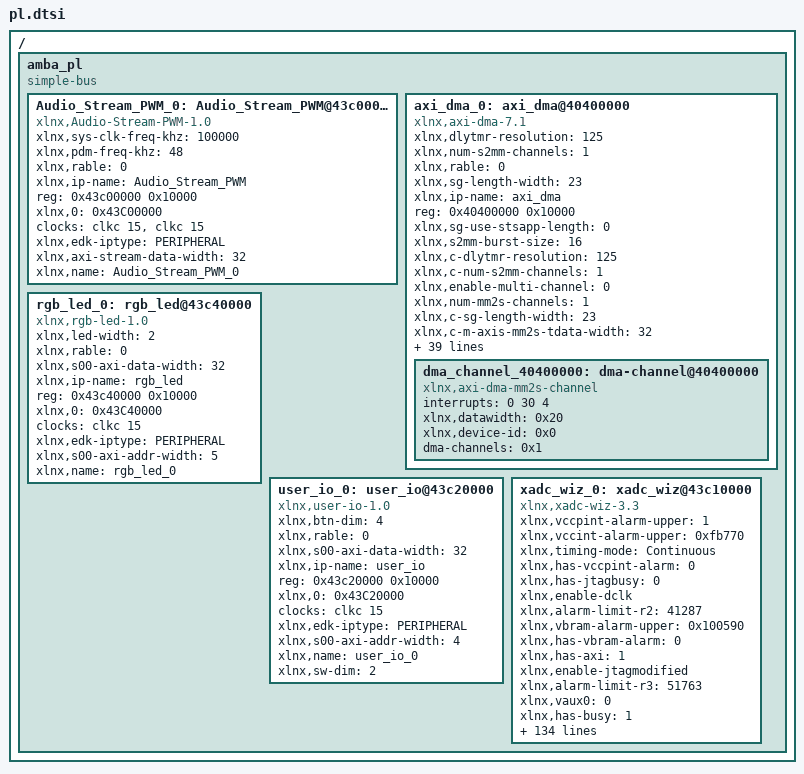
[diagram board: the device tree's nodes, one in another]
/ {
	amba_pl: amba_pl {
		ranges;
		compatible = "simple-bus";
		#address-cells = <1>;
		#size-cells = <1>;
		Audio_Stream_PWM_0: Audio_Stream_PWM@43c00000 {
			compatible = "xlnx,Audio-Stream-PWM-1.0";
			xlnx,sys-clk-freq-khz = <100000>;
			xlnx,pdm-freq-khz = <48>;
			xlnx,rable = <0>;
			xlnx,ip-name = "Audio_Stream_PWM";
			reg = <0x43c00000 0x10000>;
			xlnx,0 = <0x43C00000>;
			clocks = <&clkc 15>, <&clkc 15>;
			xlnx,edk-iptype = "PERIPHERAL";
			status = "okay";
			xlnx,axi-stream-data-width = <32>;
			clock-names = "S_AXIS_MM2S_ACLK" , "s_axi_aclk";
			xlnx,name = "Audio_Stream_PWM_0";
		};
		axi_dma_0: axi_dma@40400000 {
			xlnx,dlytmr-resolution = <125>;
			xlnx,num-s2mm-channels = <1>;
			xlnx,rable = <0>;
			xlnx,sg-length-width = <23>;
			xlnx,ip-name = "axi_dma";
			reg = <0x40400000 0x10000>;
			xlnx,sg-use-stsapp-length = <0>;
			xlnx,s2mm-burst-size = <16>;
			xlnx,c-dlytmr-resolution = <125>;
			xlnx,c-num-s2mm-channels = <1>;
			xlnx,enable-multi-channel = <0>;
			xlnx,num-mm2s-channels = <1>;
			xlnx,c-sg-length-width = <23>;
			interrupt-names = "mm2s_introut";
			compatible = "xlnx,axi-dma-7.1" , "xlnx,axi-dma-1.00.a";
			xlnx,c-m-axis-mm2s-tdata-width = <32>;
			xlnx,c-sg-use-stsapp-length = <0>;
			xlnx,c-s2mm-burst-size = <16>;
			xlnx,mm2s-burst-size = <16>;
			xlnx,c-enable-multi-channel = <0>;
			xlnx,c-num-mm2s-channels = <1>;
			interrupt-parent = <&intc>;
			xlnx,include-s2mm-dre = <0>;
			xlnx,c-mm2s-burst-size = <16>;
			status = "okay";
			xlnx,c-include-s2mm-dre = <0>;
			xlnx,include-mm2s-dre = <0>;
			xlnx,name = "axi_dma_0";
			interrupts = < 0 30 4 >;
			xlnx,c-include-sg = <0>;
			xlnx,c-m-axi-s2mm-data-width = <32>;
			xlnx,include-s2mm-sf = <1>;
			xlnx,c-include-mm2s-dre = <0>;
			xlnx,include-s2mm = <0>;
			clocks = <&clkc 15>, <&clkc 15>;
			xlnx,addrwidth = <0x20>;
			xlnx,c-m-axi-mm2s-data-width = <32>;
			xlnx,edk-iptype = "PERIPHERAL";
			xlnx,c-include-s2mm-sf = <1>;
			xlnx,include-mm2s-sf = <1>;
			clock-names = "m_axi_mm2s_aclk" , "s_axi_lite_aclk";
			xlnx,c-include-s2mm = <0>;
			xlnx,c-addr-width = <32>;
			xlnx,c-single-interface = <0>;
			xlnx,include-mm2s = <1>;
			xlnx,c-s-axis-s2mm-tdata-width = <32>;
			xlnx,s2mm-data-width = <0x20>;
			xlnx,c-include-mm2s-sf = <1>;
			xlnx,prmry-is-aclk-async = <0>;
			xlnx,c-include-mm2s = <1>;
			xlnx,increase-throughput = <0>;
			xlnx,micro-dma = <0>;
			xlnx,mm2s-data-width = <0x20>;
			xlnx,c-prmry-is-aclk-async = <0>;
			xlnx,c-sg-include-stscntrl-strm = <0>;
			xlnx,c-increase-throughput = <0>;
			xlnx,c-micro-dma = <0>;
			dma_channel_40400000: dma-channel@40400000 {
				interrupts = <0 30 4>;
				xlnx,datawidth = <0x20>;
				xlnx,device-id = <0x0>;
				compatible = "xlnx,axi-dma-mm2s-channel";
				dma-channels = <0x1>;
			};
		};
		rgb_led_0: rgb_led@43c40000 {
			compatible = "xlnx,rgb-led-1.0";
			xlnx,led-width = <2>;
			xlnx,rable = <0>;
			xlnx,s00-axi-data-width = <32>;
			xlnx,ip-name = "rgb_led";
			reg = <0x43c40000 0x10000>;
			xlnx,0 = <0x43C40000>;
			clocks = <&clkc 15>;
			xlnx,edk-iptype = "PERIPHERAL";
			status = "okay";
			xlnx,s00-axi-addr-width = <5>;
			clock-names = "s00_axi_aclk";
			xlnx,name = "rgb_led_0";
		};
		user_io_0: user_io@43c20000 {
			compatible = "xlnx,user-io-1.0";
			xlnx,btn-dim = <4>;
			xlnx,rable = <0>;
			xlnx,s00-axi-data-width = <32>;
			xlnx,ip-name = "user_io";
			reg = <0x43c20000 0x10000>;
			xlnx,0 = <0x43C20000>;
			clocks = <&clkc 15>;
			xlnx,edk-iptype = "PERIPHERAL";
			status = "okay";
			clock-names = "s00_axi_aclk";
			xlnx,s00-axi-addr-width = <4>;
			xlnx,name = "user_io_0";
			xlnx,sw-dim = <2>;
		};
		xadc_wiz_0: xadc_wiz@43c10000 {
			xlnx,vccpint-alarm-upper = <1>;
			xlnx,vccint-alarm-upper = <0xfb770>;
			xlnx,timing-mode = "Continuous";
			xlnx,has-vccpint-alarm = <0>;
			xlnx,has-jtagbusy = <0>;
			xlnx,enable-dclk;
			xlnx,alarm-limit-r2 = <41287>;
			xlnx,vbram-alarm-upper = <0x100590>;
			xlnx,has-vbram-alarm = <0>;
			xlnx,has-axi = <1>;
			xlnx,enable-jtagmodified;
			xlnx,alarm-limit-r3 = <51763>;
			xlnx,vaux0 = <0>;
			xlnx,has-busy = <1>;
			xlnx,alarm-limit-r4 = <43322>;
			xlnx,vaux1 = <1>;
			xlnx,has-vccaux-alarm = <0>;
			xlnx,enable-channel;
			xlnx,alarm-limit-r5 = <21190>;
			xlnx,dclk-frequency = <100>;
			xlnx,vaux2 = <0>;
			xlnx,rable = <0>;
			xlnx,alarm-limit-r6 = <38229>;
			xlnx,vaux3 = <0>;
			xlnx,has-drp = <0>;
			xlnx,ip-name = "xadc_wiz";
			xlnx,alarm-limit-r7 = <44622>;
			xlnx,configuration-r0 = <0>;
			xlnx,vaux4 = <0>;
			xlnx,sim-file-rel-path = "./";
			xlnx,external-mux-channel = "VP_VN";
			reg = <0x43c10000 0x10000>;
			xlnx,alarm-limit-r8 = <22937>;
			xlnx,configuration-r1 = <33039>;
			xlnx,vaux5 = <1>;
			xlnx,temperature-alarm-trigger = <85>;
			xlnx,has-jtaglocked = <0>;
			xlnx,alarm-limit-r9 = <20753>;
			xlnx,c-component-name = "design_1_xadc_wiz_0_0";
			xlnx,configuration-r2 = <1024>;
			xlnx,vaux6 = <1>;
			xlnx,vaux7 = <0>;
			xlnx,vaux8 = <0>;
			xlnx,vaux9 = <1>;
			xlnx,vaux10 = <0>;
			xlnx,has-vn = <1>;
			xlnx,has-vccpaux-alarm = <0>;
			xlnx,acquisition-time = <4>;
			xlnx,channel-enable-vauxp13-vauxn13;
			xlnx,vaux11 = <0>;
			xlnx,has-temp-bus = <0>;
			xlnx,xadc-starup-selection = "independent_adc";
			xlnx,vaux12 = <0>;
			xlnx,sim-file-sel = "Default";
			xlnx,has-vp = <1>;
			xlnx,data-width = <32>;
			xlnx,enable-busy;
			xlnx,ip-type = <0x0>;
			interrupt-names = "ip2intc_irpt";
			xlnx,vaux13 = <1>;
			xlnx,temperature-alarm-ot-reset = <70>;
			xlnx,vaux14 = <0>;
			xlnx,enable-convst;
			xlnx,channel-enable-vauxp15-vauxn15;
			xlnx,channel-enable-vp-vn;
			xlnx,vccpaux-alarm-lower = <0x1a17b0>;
			xlnx,vccaux-alarm-lower = <0x1ab3f0>;
			xlnx,vaux15 = <1>;
			compatible = "xlnx,xadc-wiz-3.3" , "xlnx,axi-xadc-1.00.a";
			xlnx,has-external-mux = <0>;
			xlnx,average-enable-vp-vn;
			xlnx,sampling-rate = <0x7fffffff>;
			xlnx,has-reset = <0>;
			xlnx,adc-conversion-rate = <1000>;
			xlnx,vccddro-alarm-lower = <0x124f80>;
			xlnx,has-user-temp-alarm = <0>;
			xlnx,enable-calibration-averaging;
			interrupt-parent = <&intc>;
			xlnx,has-ot-alarm = <0>;
			xlnx,has-convst = <0>;
			xlnx,channel-enable-vauxp1-vauxn1;
			xlnx,average-enable-vauxp1-vauxn1;
			xlnx,single-channel-selection = "TEMPERATURE";
			xlnx,startup-channel-selection = "single_channel";
			xlnx,interface-selection = "Enable_AXI";
			xlnx,vccpaux-alarm-upper = <0x1b7740>;
			xlnx,vccaux-alarm-upper = <0x1cd6d0>;
			status = "okay";
			xlnx,sensor-offset-and-gain-calibration;
			xlnx,vccddro-alarm-upper = <0x1312d0>;
			xlnx,name = "xadc_wiz_0";
			xlnx,external-mux = "none";
			interrupts = < 0 29 4 >;
			xlnx,enable-eoc;
			xlnx,sim-file-name = "design";
			xlnx,enable-jtaglocked;
			xlnx,channel-enable-vauxp9-vauxn9;
			xlnx,temperature-alarm-reset = <60>;
			xlnx,addr-width = <32>;
			clocks = <&clkc 15>;
			xlnx,alarm-limit-r10 = <21845>;
			xlnx,average-enable-vauxp9-vauxn9;
			xlnx,alarm-limit-r11 = <20753>;
			xlnx,alarm-limit-r12 = <39321>;
			xlnx,alarm-limit-r13 = <37355>;
			xlnx,edk-iptype = "PERIPHERAL";
			xlnx,sequencer-mode;
			xlnx,enable-jtagbusy;
			xlnx,alarm-limit-r14 = <27306>;
			xlnx,include-intr = <1>;
			xlnx,fifo-depth = <7>;
			xlnx,alarm-limit-r15 = <26214>;
			clock-names = "s_axi_aclk";
			xlnx,average-enable-vauxp13-vauxn13;
			xlnx,has-eoc = <1>;
			xlnx,temperature-alarm-ot-trigger = <125>;
			xlnx,has-channel = <1>;
			xlnx,enable-eos;
			xlnx,average-enable-vauxp15-vauxn15;
			xlnx,vccpint-alarm-lower = <0xe7ef0>;
			xlnx,vccint-alarm-lower = <0xecd10>;
			xlnx,has-dclk = <1>;
			xlnx,vbram-alarm-lower = <0xe7ef0>;
			xlnx,sequence-r0 = <2048>;
			xlnx,num-wave = <1>;
			xlnx,has-jtagmodified = <0>;
			xlnx,sequence-r1 = <41570>;
			xlnx,channel-enable-vauxp6-vauxn6;
			xlnx,sequence-r2 = <2048>;
			xlnx,has-vccint-alarm = <0>;
			xlnx,enable-drp;
			xlnx,channel-averaging = "None";
			xlnx,sequence-r3 = <41570>;
			xlnx,has-axi4stream = <0>;
			xlnx,average-enable-vauxp6-vauxn6;
			xlnx,sequence-r4 = <0>;
			xlnx,sequence-r5 = <0>;
			xlnx,adc-offset-and-gain-calibration;
			xlnx,waveform-type = "CONSTANT";
			xlnx,sequence-r6 = <0>;
			xlnx,vccddro-volt = "1_2";
			xlnx,sequence-r7 = <0>;
			xlnx,channel-enable-vauxp5-vauxn5;
			xlnx,has-vccddro-alarm = <0>;
			xlnx,has-eos = <1>;
			xlnx,has-convstclk = <0>;
			xlnx,alarm-limit-r0 = <46573>;
			xlnx,stimulus-freq = <1>;
			xlnx,single-channel-enable-calibration;
			xlnx,external-muxaddr-enable = <0>;
			xlnx,alarm-limit-r1 = <22500>;
			xlnx,average-enable-vauxp5-vauxn5;
		};
	};
};
